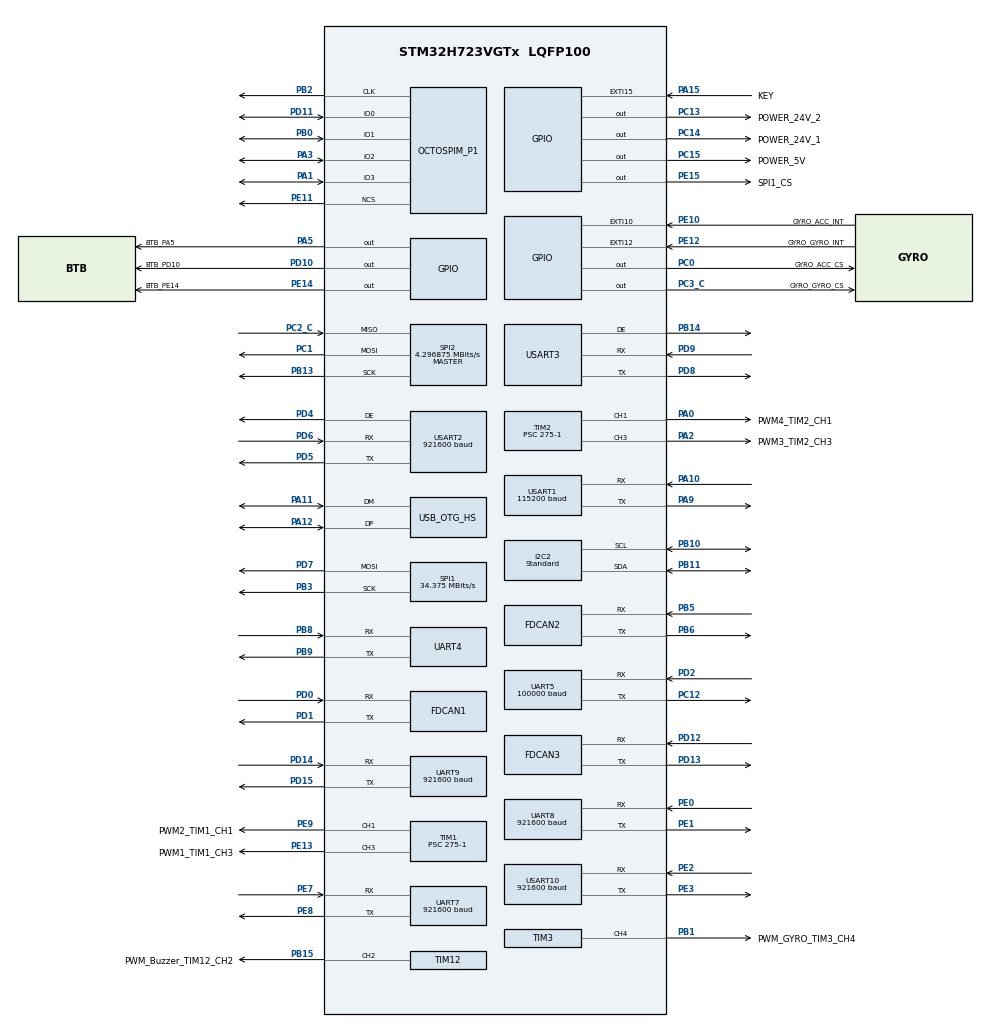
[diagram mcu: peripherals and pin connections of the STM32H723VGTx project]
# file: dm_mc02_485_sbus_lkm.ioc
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CORTEX_M7.BaseAddress-Cortex_Memory_Protection_Unit_Region0_Settings=0x24000000
CORTEX_M7.CPU_DCache=Disabled
CORTEX_M7.CPU_ICache=Disabled
CORTEX_M7.Enable-Cortex_Memory_Protection_Unit_Region0_Settings=MPU_REGION_ENABLE
CORTEX_M7.IsBufferable-Cortex_Memory_Protection_Unit_Region0_Settings=MPU_ACCESS_BUFFERABLE
CORTEX_M7.IsCacheable-Cortex_Memory_Protection_Unit_Region0_Settings=MPU_ACCESS_CACHEABLE
CORTEX_M7.MPU_Control=__NULL
CORTEX_M7.Size-Cortex_Memory_Protection_Unit_Region0_Settings=MPU_REGION_SIZE_512B
CORTEX_M7.TypeExtField-Cortex_Memory_Protection_Unit_Region0_Settings=MPU_TEX_LEVEL1
Dma.Request0=USART1_RX
Dma.Request1=USART1_TX
Dma.Request10=USART10_RX
Dma.Request11=USART10_TX
Dma.Request12=USART2_RX
Dma.Request13=USART2_TX
Dma.Request2=UART4_RX
Dma.Request3=UART4_TX
Dma.Request4=UART7_RX
Dma.Request5=UART7_TX
Dma.Request6=UART8_RX
Dma.Request7=UART8_TX
Dma.Request8=UART9_RX
Dma.Request9=UART9_TX
Dma.UART4_RX.2.Direction=DMA_PERIPH_TO_MEMORY
Dma.UART4_RX.2.EventEnable=DISABLE
Dma.UART4_RX.2.FIFOMode=DMA_FIFOMODE_DISABLE
Dma.UART4_RX.2.Instance=DMA1_Stream3
Dma.UART4_RX.2.MemDataAlignment=DMA_MDATAALIGN_BYTE
Dma.UART4_RX.2.MemInc=DMA_MINC_ENABLE
Dma.UART4_RX.2.Mode=DMA_NORMAL
Dma.UART4_RX.2.PeriphDataAlignment=DMA_PDATAALIGN_BYTE
Dma.UART4_RX.2.PeriphInc=DMA_PINC_DISABLE
Dma.UART4_RX.2.Polarity=HAL_DMAMUX_REQ_GEN_RISING
Dma.UART4_RX.2.Priority=DMA_PRIORITY_LOW
Dma.UART4_RX.2.RequestNumber=1
Dma.UART4_RX.2.SignalID=NONE
Dma.UART4_RX.2.SyncEnable=DISABLE
Dma.UART4_RX.2.SyncPolarity=HAL_DMAMUX_SYNC_NO_EVENT
Dma.UART4_RX.2.SyncRequestNumber=1
Dma.UART4_RX.2.SyncSignalID=NONE
Dma.UART4_TX.3.Direction=DMA_MEMORY_TO_PERIPH
Dma.UART4_TX.3.EventEnable=DISABLE
Dma.UART4_TX.3.FIFOMode=DMA_FIFOMODE_ENABLE
Dma.UART4_TX.3.FIFOThreshold=DMA_FIFO_THRESHOLD_HALFFULL
Dma.UART4_TX.3.Instance=DMA1_Stream4
Dma.UART4_TX.3.MemBurst=DMA_MBURST_SINGLE
Dma.UART4_TX.3.MemDataAlignment=DMA_MDATAALIGN_BYTE
Dma.UART4_TX.3.MemInc=DMA_MINC_ENABLE
Dma.UART4_TX.3.Mode=DMA_NORMAL
Dma.UART4_TX.3.PeriphBurst=DMA_PBURST_SINGLE
Dma.UART4_TX.3.PeriphDataAlignment=DMA_PDATAALIGN_BYTE
Dma.UART4_TX.3.PeriphInc=DMA_PINC_DISABLE
Dma.UART4_TX.3.Polarity=HAL_DMAMUX_REQ_GEN_RISING
Dma.UART4_TX.3.Priority=DMA_PRIORITY_LOW
Dma.UART4_TX.3.RequestNumber=1
Dma.UART4_TX.3.SignalID=NONE
Dma.UART4_TX.3.SyncEnable=DISABLE
Dma.UART4_TX.3.SyncPolarity=HAL_DMAMUX_SYNC_NO_EVENT
Dma.UART4_TX.3.SyncRequestNumber=1
Dma.UART4_TX.3.SyncSignalID=NONE
Dma.UART7_RX.4.Direction=DMA_PERIPH_TO_MEMORY
Dma.UART7_RX.4.EventEnable=DISABLE
Dma.UART7_RX.4.FIFOMode=DMA_FIFOMODE_DISABLE
Dma.UART7_RX.4.Instance=DMA1_Stream5
Dma.UART7_RX.4.MemDataAlignment=DMA_MDATAALIGN_BYTE
Dma.UART7_RX.4.MemInc=DMA_MINC_ENABLE
Dma.UART7_RX.4.Mode=DMA_NORMAL
Dma.UART7_RX.4.PeriphDataAlignment=DMA_PDATAALIGN_BYTE
Dma.UART7_RX.4.PeriphInc=DMA_PINC_DISABLE
Dma.UART7_RX.4.Polarity=HAL_DMAMUX_REQ_GEN_RISING
Dma.UART7_RX.4.Priority=DMA_PRIORITY_LOW
Dma.UART7_RX.4.RequestNumber=1
Dma.UART7_RX.4.SignalID=NONE
Dma.UART7_RX.4.SyncEnable=DISABLE
Dma.UART7_RX.4.SyncPolarity=HAL_DMAMUX_SYNC_NO_EVENT
Dma.UART7_RX.4.SyncRequestNumber=1
Dma.UART7_RX.4.SyncSignalID=NONE
Dma.UART7_TX.5.Direction=DMA_MEMORY_TO_PERIPH
Dma.UART7_TX.5.EventEnable=DISABLE
Dma.UART7_TX.5.FIFOMode=DMA_FIFOMODE_ENABLE
Dma.UART7_TX.5.FIFOThreshold=DMA_FIFO_THRESHOLD_HALFFULL
Dma.UART7_TX.5.Instance=DMA1_Stream6
Dma.UART7_TX.5.MemBurst=DMA_MBURST_SINGLE
Dma.UART7_TX.5.MemDataAlignment=DMA_MDATAALIGN_BYTE
Dma.UART7_TX.5.MemInc=DMA_MINC_ENABLE
Dma.UART7_TX.5.Mode=DMA_NORMAL
Dma.UART7_TX.5.PeriphBurst=DMA_PBURST_SINGLE
Dma.UART7_TX.5.PeriphDataAlignment=DMA_PDATAALIGN_BYTE
Dma.UART7_TX.5.PeriphInc=DMA_PINC_DISABLE
Dma.UART7_TX.5.Polarity=HAL_DMAMUX_REQ_GEN_RISING
Dma.UART7_TX.5.Priority=DMA_PRIORITY_LOW
Dma.UART7_TX.5.RequestNumber=1
Dma.UART7_TX.5.SignalID=NONE
Dma.UART7_TX.5.SyncEnable=DISABLE
Dma.UART7_TX.5.SyncPolarity=HAL_DMAMUX_SYNC_NO_EVENT
Dma.UART7_TX.5.SyncRequestNumber=1
Dma.UART7_TX.5.SyncSignalID=NONE
Dma.UART8_RX.6.Direction=DMA_PERIPH_TO_MEMORY
Dma.UART8_RX.6.EventEnable=DISABLE
Dma.UART8_RX.6.FIFOMode=DMA_FIFOMODE_DISABLE
Dma.UART8_RX.6.Instance=DMA1_Stream7
Dma.UART8_RX.6.MemDataAlignment=DMA_MDATAALIGN_BYTE
Dma.UART8_RX.6.MemInc=DMA_MINC_ENABLE
Dma.UART8_RX.6.Mode=DMA_NORMAL
Dma.UART8_RX.6.PeriphDataAlignment=DMA_PDATAALIGN_BYTE
Dma.UART8_RX.6.PeriphInc=DMA_PINC_DISABLE
Dma.UART8_RX.6.Polarity=HAL_DMAMUX_REQ_GEN_RISING
Dma.UART8_RX.6.Priority=DMA_PRIORITY_LOW
Dma.UART8_RX.6.RequestNumber=1
Dma.UART8_RX.6.SignalID=NONE
Dma.UART8_RX.6.SyncEnable=DISABLE
Dma.UART8_RX.6.SyncPolarity=HAL_DMAMUX_SYNC_NO_EVENT
Dma.UART8_RX.6.SyncRequestNumber=1
Dma.UART8_RX.6.SyncSignalID=NONE
Dma.UART8_TX.7.Direction=DMA_MEMORY_TO_PERIPH
Dma.UART8_TX.7.EventEnable=DISABLE
Dma.UART8_TX.7.FIFOMode=DMA_FIFOMODE_ENABLE
Dma.UART8_TX.7.FIFOThreshold=DMA_FIFO_THRESHOLD_HALFFULL
Dma.UART8_TX.7.Instance=DMA2_Stream0
Dma.UART8_TX.7.MemBurst=DMA_MBURST_SINGLE
Dma.UART8_TX.7.MemDataAlignment=DMA_MDATAALIGN_BYTE
Dma.UART8_TX.7.MemInc=DMA_MINC_ENABLE
Dma.UART8_TX.7.Mode=DMA_NORMAL
Dma.UART8_TX.7.PeriphBurst=DMA_PBURST_SINGLE
Dma.UART8_TX.7.PeriphDataAlignment=DMA_PDATAALIGN_BYTE
Dma.UART8_TX.7.PeriphInc=DMA_PINC_DISABLE
Dma.UART8_TX.7.Polarity=HAL_DMAMUX_REQ_GEN_RISING
Dma.UART8_TX.7.Priority=DMA_PRIORITY_LOW
Dma.UART8_TX.7.RequestNumber=1
Dma.UART8_TX.7.SignalID=NONE
Dma.UART8_TX.7.SyncEnable=DISABLE
Dma.UART8_TX.7.SyncPolarity=HAL_DMAMUX_SYNC_NO_EVENT
Dma.UART8_TX.7.SyncRequestNumber=1
Dma.UART8_TX.7.SyncSignalID=NONE
Dma.UART9_RX.8.Direction=DMA_PERIPH_TO_MEMORY
Dma.UART9_RX.8.EventEnable=DISABLE
Dma.UART9_RX.8.FIFOMode=DMA_FIFOMODE_DISABLE
Dma.UART9_RX.8.Instance=DMA2_Stream1
Dma.UART9_RX.8.MemDataAlignment=DMA_MDATAALIGN_BYTE
Dma.UART9_RX.8.MemInc=DMA_MINC_ENABLE
Dma.UART9_RX.8.Mode=DMA_NORMAL
Dma.UART9_RX.8.PeriphDataAlignment=DMA_PDATAALIGN_BYTE
Dma.UART9_RX.8.PeriphInc=DMA_PINC_DISABLE
Dma.UART9_RX.8.Polarity=HAL_DMAMUX_REQ_GEN_RISING
Dma.UART9_RX.8.Priority=DMA_PRIORITY_LOW
Dma.UART9_RX.8.RequestNumber=1
Dma.UART9_RX.8.SignalID=NONE
Dma.UART9_RX.8.SyncEnable=DISABLE
Dma.UART9_RX.8.SyncPolarity=HAL_DMAMUX_SYNC_NO_EVENT
Dma.UART9_RX.8.SyncRequestNumber=1
Dma.UART9_RX.8.SyncSignalID=NONE
Dma.UART9_TX.9.Direction=DMA_MEMORY_TO_PERIPH
Dma.UART9_TX.9.EventEnable=DISABLE
Dma.UART9_TX.9.FIFOMode=DMA_FIFOMODE_ENABLE
Dma.UART9_TX.9.FIFOThreshold=DMA_FIFO_THRESHOLD_HALFFULL
Dma.UART9_TX.9.Instance=DMA2_Stream2
Dma.UART9_TX.9.MemBurst=DMA_MBURST_SINGLE
Dma.UART9_TX.9.MemDataAlignment=DMA_MDATAALIGN_BYTE
Dma.UART9_TX.9.MemInc=DMA_MINC_ENABLE
Dma.UART9_TX.9.Mode=DMA_NORMAL
Dma.UART9_TX.9.PeriphBurst=DMA_PBURST_SINGLE
Dma.UART9_TX.9.PeriphDataAlignment=DMA_PDATAALIGN_BYTE
Dma.UART9_TX.9.PeriphInc=DMA_PINC_DISABLE
Dma.UART9_TX.9.Polarity=HAL_DMAMUX_REQ_GEN_RISING
Dma.UART9_TX.9.Priority=DMA_PRIORITY_LOW
Dma.UART9_TX.9.RequestNumber=1
Dma.UART9_TX.9.SignalID=NONE
Dma.UART9_TX.9.SyncEnable=DISABLE
Dma.UART9_TX.9.SyncPolarity=HAL_DMAMUX_SYNC_NO_EVENT
Dma.UART9_TX.9.SyncRequestNumber=1
Dma.UART9_TX.9.SyncSignalID=NONE
Dma.USART10_RX.10.Direction=DMA_PERIPH_TO_MEMORY
Dma.USART10_RX.10.EventEnable=DISABLE
Dma.USART10_RX.10.FIFOMode=DMA_FIFOMODE_DISABLE
Dma.USART10_RX.10.Instance=DMA2_Stream3
Dma.USART10_RX.10.MemDataAlignment=DMA_MDATAALIGN_BYTE
Dma.USART10_RX.10.MemInc=DMA_MINC_ENABLE
Dma.USART10_RX.10.Mode=DMA_NORMAL
Dma.USART10_RX.10.PeriphDataAlignment=DMA_PDATAALIGN_BYTE
Dma.USART10_RX.10.PeriphInc=DMA_PINC_DISABLE
Dma.USART10_RX.10.Polarity=HAL_DMAMUX_REQ_GEN_RISING
Dma.USART10_RX.10.Priority=DMA_PRIORITY_LOW
Dma.USART10_RX.10.RequestNumber=1
Dma.USART10_RX.10.SignalID=NONE
Dma.USART10_RX.10.SyncEnable=DISABLE
Dma.USART10_RX.10.SyncPolarity=HAL_DMAMUX_SYNC_NO_EVENT
Dma.USART10_RX.10.SyncRequestNumber=1
Dma.USART10_RX.10.SyncSignalID=NONE
Dma.USART10_TX.11.Direction=DMA_MEMORY_TO_PERIPH
Dma.USART10_TX.11.EventEnable=DISABLE
Dma.USART10_TX.11.FIFOMode=DMA_FIFOMODE_ENABLE
Dma.USART10_TX.11.FIFOThreshold=DMA_FIFO_THRESHOLD_HALFFULL
Dma.USART10_TX.11.Instance=DMA2_Stream4
Dma.USART10_TX.11.MemBurst=DMA_MBURST_SINGLE
Dma.USART10_TX.11.MemDataAlignment=DMA_MDATAALIGN_BYTE
Dma.USART10_TX.11.MemInc=DMA_MINC_ENABLE
Dma.USART10_TX.11.Mode=DMA_NORMAL
Dma.USART10_TX.11.PeriphBurst=DMA_PBURST_SINGLE
Dma.USART10_TX.11.PeriphDataAlignment=DMA_PDATAALIGN_BYTE
Dma.USART10_TX.11.PeriphInc=DMA_PINC_DISABLE
Dma.USART10_TX.11.Polarity=HAL_DMAMUX_REQ_GEN_RISING
Dma.USART10_TX.11.Priority=DMA_PRIORITY_LOW
Dma.USART10_TX.11.RequestNumber=1
Dma.USART10_TX.11.SignalID=NONE
Dma.USART10_TX.11.SyncEnable=DISABLE
Dma.USART10_TX.11.SyncPolarity=HAL_DMAMUX_SYNC_NO_EVENT
Dma.USART10_TX.11.SyncRequestNumber=1
Dma.USART10_TX.11.SyncSignalID=NONE
Dma.USART1_RX.0.Direction=DMA_PERIPH_TO_MEMORY
Dma.USART1_RX.0.EventEnable=DISABLE
Dma.USART1_RX.0.FIFOMode=DMA_FIFOMODE_DISABLE
Dma.USART1_RX.0.Instance=DMA1_Stream1
Dma.USART1_RX.0.MemDataAlignment=DMA_MDATAALIGN_BYTE
Dma.USART1_RX.0.MemInc=DMA_MINC_ENABLE
Dma.USART1_RX.0.Mode=DMA_NORMAL
Dma.USART1_RX.0.PeriphDataAlignment=DMA_PDATAALIGN_BYTE
Dma.USART1_RX.0.PeriphInc=DMA_PINC_DISABLE
Dma.USART1_RX.0.Polarity=HAL_DMAMUX_REQ_GEN_RISING
Dma.USART1_RX.0.Priority=DMA_PRIORITY_LOW
Dma.USART1_RX.0.RequestNumber=1
Dma.USART1_RX.0.SignalID=NONE
Dma.USART1_RX.0.SyncEnable=DISABLE
Dma.USART1_RX.0.SyncPolarity=HAL_DMAMUX_SYNC_NO_EVENT
Dma.USART1_RX.0.SyncRequestNumber=1
Dma.USART1_RX.0.SyncSignalID=NONE
Dma.USART1_TX.1.Direction=DMA_MEMORY_TO_PERIPH
Dma.USART1_TX.1.EventEnable=DISABLE
Dma.USART1_TX.1.FIFOMode=DMA_FIFOMODE_ENABLE
Dma.USART1_TX.1.FIFOThreshold=DMA_FIFO_THRESHOLD_HALFFULL
Dma.USART1_TX.1.Instance=DMA1_Stream2
Dma.USART1_TX.1.MemBurst=DMA_MBURST_SINGLE
Dma.USART1_TX.1.MemDataAlignment=DMA_MDATAALIGN_BYTE
Dma.USART1_TX.1.MemInc=DMA_MINC_ENABLE
Dma.USART1_TX.1.Mode=DMA_NORMAL
Dma.USART1_TX.1.PeriphBurst=DMA_PBURST_SINGLE
Dma.USART1_TX.1.PeriphDataAlignment=DMA_PDATAALIGN_BYTE
Dma.USART1_TX.1.PeriphInc=DMA_PINC_DISABLE
Dma.USART1_TX.1.Polarity=HAL_DMAMUX_REQ_GEN_RISING
Dma.USART1_TX.1.Priority=DMA_PRIORITY_LOW
Dma.USART1_TX.1.RequestNumber=1
Dma.USART1_TX.1.SignalID=NONE
Dma.USART1_TX.1.SyncEnable=DISABLE
Dma.USART1_TX.1.SyncPolarity=HAL_DMAMUX_SYNC_NO_EVENT
Dma.USART1_TX.1.SyncRequestNumber=1
Dma.USART1_TX.1.SyncSignalID=NONE
Dma.USART2_RX.12.Direction=DMA_PERIPH_TO_MEMORY
Dma.USART2_RX.12.EventEnable=DISABLE
Dma.USART2_RX.12.FIFOMode=DMA_FIFOMODE_DISABLE
Dma.USART2_RX.12.Instance=DMA1_Stream0
Dma.USART2_RX.12.MemDataAlignment=DMA_MDATAALIGN_BYTE
Dma.USART2_RX.12.MemInc=DMA_MINC_ENABLE
Dma.USART2_RX.12.Mode=DMA_NORMAL
Dma.USART2_RX.12.PeriphDataAlignment=DMA_PDATAALIGN_BYTE
Dma.USART2_RX.12.PeriphInc=DMA_PINC_DISABLE
Dma.USART2_RX.12.Polarity=HAL_DMAMUX_REQ_GEN_RISING
Dma.USART2_RX.12.Priority=DMA_PRIORITY_LOW
Dma.USART2_RX.12.RequestNumber=1
Dma.USART2_RX.12.SignalID=NONE
Dma.USART2_RX.12.SyncEnable=DISABLE
Dma.USART2_RX.12.SyncPolarity=HAL_DMAMUX_SYNC_NO_EVENT
Dma.USART2_RX.12.SyncRequestNumber=1
Dma.USART2_RX.12.SyncSignalID=NONE
Dma.USART2_TX.13.Direction=DMA_MEMORY_TO_PERIPH
Dma.USART2_TX.13.EventEnable=DISABLE
Dma.USART2_TX.13.FIFOMode=DMA_FIFOMODE_DISABLE
Dma.USART2_TX.13.Instance=DMA2_Stream5
Dma.USART2_TX.13.MemDataAlignment=DMA_MDATAALIGN_BYTE
Dma.USART2_TX.13.MemInc=DMA_MINC_ENABLE
Dma.USART2_TX.13.Mode=DMA_NORMAL
Dma.USART2_TX.13.PeriphDataAlignment=DMA_PDATAALIGN_BYTE
Dma.USART2_TX.13.PeriphInc=DMA_PINC_DISABLE
Dma.USART2_TX.13.Polarity=HAL_DMAMUX_REQ_GEN_RISING
Dma.USART2_TX.13.Priority=DMA_PRIORITY_LOW
Dma.USART2_TX.13.RequestNumber=1
Dma.USART2_TX.13.SignalID=NONE
Dma.USART2_TX.13.SyncEnable=DISABLE
Dma.USART2_TX.13.SyncPolarity=HAL_DMAMUX_SYNC_NO_EVENT
Dma.USART2_TX.13.SyncRequestNumber=1
Dma.USART2_TX.13.SyncSignalID=NONE
FDCAN1.AutoRetransmission=ENABLE
FDCAN1.CalculateBaudRateNominal=1000000
FDCAN1.CalculateTimeBitNominal=1000
FDCAN1.CalculateTimeQuantumNominal=62.5
FDCAN1.NominalPrescaler=6
FDCAN1.NominalTimeSeg1=11
FDCAN1.NominalTimeSeg2=4
FDCAN1.RxFifo0ElmtsNbr=16
FDCAN1.StdFiltersNbr=1
FDCAN1.TxFifoQueueElmtsNbr=16
FDCAN2.AutoRetransmission=ENABLE
FDCAN2.CalculateBaudRateNominal=1000000
FDCAN2.CalculateTimeBitNominal=1000
FDCAN2.CalculateTimeQuantumNominal=62.5
FDCAN2.MessageRAMOffset=129
FDCAN2.NominalPrescaler=6
FDCAN2.NominalTimeSeg1=11
FDCAN2.NominalTimeSeg2=4
FDCAN2.RxFifo0ElmtsNbr=16
FDCAN2.StdFiltersNbr=1
FDCAN2.TxFifoQueueElmtsNbr=16
FDCAN3.AutoRetransmission=ENABLE
FDCAN3.CalculateBaudRateNominal=1000000
FDCAN3.CalculateTimeBitNominal=1000
FDCAN3.CalculateTimeQuantumNominal=62.5
FDCAN3.MessageRAMOffset=258
FDCAN3.NominalPrescaler=6
FDCAN3.NominalTimeSeg1=11
FDCAN3.NominalTimeSeg2=4
FDCAN3.RxFifo0ElmtsNbr=16
FDCAN3.StdFiltersNbr=1
FDCAN3.TxFifoQueueElmtsNbr=16
FREERTOS.INCLUDE_eTaskGetState=1
FREERTOS.INCLUDE_uxTaskGetStackHighWaterMark=1
FREERTOS.INCLUDE_vTaskDelayUntil=1
FREERTOS.INCLUDE_xQueueGetMutexHolder=1
FREERTOS.INCLUDE_xTaskGetCurrentTaskHandle=1
FREERTOS.INCLUDE_xTimerPendFunctionCall=1
FREERTOS.Tasks01=defaultTask,24,512,StartDefaultTask,As weak,NULL,Dynamic,NULL,NULL
FREERTOS.configCHECK_FOR_STACK_OVERFLOW=2
FREERTOS.configENABLE_FPU=1
FREERTOS.configTOTAL_HEAP_SIZE=49152
FREERTOS.configUSE_COUNTING_SEMAPHORES=1
FREERTOS.configUSE_MALLOC_FAILED_HOOK=1
FREERTOS.configUSE_NEWLIB_REENTRANT=1
FREERTOS.configUSE_RECURSIVE_MUTEXES=1
FREERTOS.configUSE_TIMERS=1
FREERTOS.configUSE_TRACE_FACILITY=1
I2C2.I2C_Speed_Mode=I2C_Standard
I2C2.Timing=0x60404E72
Mcu.Family=STM32H7
Mcu.Name=STM32H723VGTx
Mcu.Package=LQFP100
NVIC.DMA1_Stream0_IRQn=true\:5\:0\:false\:false\:true\:true\:false\:true\:true
NVIC.DMA1_Stream1_IRQn=true\:5\:0\:false\:false\:true\:true\:false\:true\:true
NVIC.DMA1_Stream2_IRQn=true\:5\:0\:false\:false\:true\:true\:false\:true\:true
NVIC.DMA1_Stream3_IRQn=true\:5\:0\:false\:false\:true\:true\:false\:true\:true
NVIC.DMA1_Stream4_IRQn=true\:5\:0\:false\:false\:true\:true\:false\:true\:true
NVIC.DMA1_Stream5_IRQn=true\:5\:0\:false\:false\:true\:true\:false\:true\:true
NVIC.DMA1_Stream6_IRQn=true\:5\:0\:false\:false\:true\:true\:false\:true\:true
NVIC.DMA1_Stream7_IRQn=true\:5\:0\:false\:false\:true\:true\:false\:true\:true
NVIC.DMA2_Stream0_IRQn=true\:5\:0\:false\:false\:true\:true\:false\:true\:true
NVIC.DMA2_Stream1_IRQn=true\:5\:0\:false\:false\:true\:true\:false\:true\:true
NVIC.DMA2_Stream2_IRQn=true\:5\:0\:false\:false\:true\:true\:false\:true\:true
NVIC.DMA2_Stream3_IRQn=true\:5\:0\:false\:false\:true\:true\:false\:true\:true
NVIC.DMA2_Stream4_IRQn=true\:5\:0\:false\:false\:true\:true\:false\:true\:true
NVIC.DMA2_Stream5_IRQn=true\:5\:0\:false\:false\:true\:true\:false\:true\:true
NVIC.EXTI15_10_IRQn=true\:5\:0\:false\:false\:true\:true\:true\:true\:true
NVIC.FDCAN1_IT0_IRQn=true\:5\:0\:false\:false\:true\:true\:true\:true\:true
NVIC.FDCAN1_IT1_IRQn=true\:5\:0\:false\:false\:true\:true\:true\:true\:true
NVIC.FDCAN2_IT0_IRQn=true\:5\:0\:false\:false\:true\:true\:true\:true\:true
NVIC.FDCAN2_IT1_IRQn=true\:5\:0\:false\:false\:true\:true\:true\:true\:true
NVIC.FDCAN3_IT0_IRQn=true\:5\:0\:false\:false\:true\:true\:true\:true\:true
NVIC.FDCAN3_IT1_IRQn=true\:5\:0\:false\:false\:true\:true\:true\:true\:true
NVIC.PriorityGroup=NVIC_PRIORITYGROUP_4
NVIC.TIM8_UP_TIM13_IRQn=true\:15\:0\:false\:false\:true\:false\:false\:true\:true
NVIC.TimeBase=TIM8_UP_TIM13_IRQn
NVIC.TimeBaseIP=TIM8
NVIC.UART4_IRQn=true\:5\:0\:false\:false\:true\:true\:true\:true\:true
NVIC.UART5_IRQn=true\:5\:0\:false\:false\:true\:true\:true\:true\:true
NVIC.UART7_IRQn=true\:5\:0\:true\:false\:true\:true\:true\:true\:true
NVIC.UART8_IRQn=true\:5\:0\:false\:false\:true\:true\:true\:true\:true
NVIC.UART9_IRQn=true\:5\:0\:false\:false\:true\:true\:true\:true\:true
NVIC.USART10_IRQn=true\:5\:0\:true\:false\:true\:true\:true\:true\:true
NVIC.USART1_IRQn=true\:5\:0\:true\:false\:true\:true\:true\:true\:true
NVIC.USART2_IRQn=true\:5\:0\:false\:false\:true\:true\:true\:true\:true
OCTOSPI2.ClockMode=HAL_OSPI_CLOCK_MODE_3
OCTOSPI2.ClockPrescaler=3
OCTOSPI2.DeviceSize=23
OCTOSPI2.DeviceType=SPI_DEVICE_FLASH
OCTOSPI2.FifoThreshold=8
OCTOSPI2.SampleShifting=HAL_OSPI_SAMPLE_SHIFTING_HALFCYCLE
PA0.GPIO_Label=PWM4_TIM2_CH1
PA0.Signal=S_TIM2_CH1_ETR
PA1.Mode=OCTOSPI2_IOL_Port1L
PA1.Signal=OCTOSPIM_P1_IO3
PA10.Mode=Asynchronous
PA10.Signal=USART1_RX
PA11.Mode=Device_Only_FS
PA11.Signal=USB_OTG_HS_DM
PA12.Mode=Device_Only_FS
PA12.Signal=USB_OTG_HS_DP
PA13(JTMS/SWDIO).Mode=Serial_Wire
PA13(JTMS/SWDIO).Signal=DEBUG_JTMS-SWDIO
PA14(JTCK/SWCLK).Mode=Serial_Wire
PA14(JTCK/SWCLK).Signal=DEBUG_JTCK-SWCLK
PA15(JTDI).GPIO_Label=KEY
PA15(JTDI).GPIO_ModeDefaultEXTI=GPIO_MODE_IT_RISING
PA15(JTDI).Signal=GPXTI15
PA2.GPIO_Label=PWM3_TIM2_CH3
PA2.Signal=S_TIM2_CH3
PA3.Mode=OCTOSPI2_IOL_Port1L
PA3.Signal=OCTOSPIM_P1_IO2
PA5.GPIO_Label=BTB_PA5
PA5.Signal=GPIO_Output
PA7.Signal=S_TIM14_CH1
PA9.Mode=Asynchronous
PA9.Signal=USART1_TX
PB0.Mode=OCTOSPI2_IOL_Port1L
PB0.Signal=OCTOSPIM_P1_IO1
PB1.GPIO_Label=PWM_GYRO_TIM3_CH4
PB1.Signal=S_TIM3_CH4
PB10.Mode=I2C
PB10.Signal=I2C2_SCL
PB11.Mode=I2C
PB11.Signal=I2C2_SDA
PB13.GPIO_Speed=GPIO_SPEED_FREQ_VERY_HIGH
PB13.Mode=Full_Duplex_Master
PB13.Signal=SPI2_SCK
PB14.Mode=Hardware Flow Control (RS485)
PB14.Signal=USART3_DE
PB15.GPIO_Label=PWM_Buzzer_TIM12_CH2
PB15.Signal=S_TIM12_CH2
PB2.Mode=O2_P1_CLK
PB2.Signal=OCTOSPIM_P1_CLK
PB3(JTDO/TRACESWO).GPIO_Speed=GPIO_SPEED_FREQ_VERY_HIGH
PB3(JTDO/TRACESWO).Mode=TX_Only_Simplex_Unidirect_Master
PB3(JTDO/TRACESWO).Signal=SPI1_SCK
PB5.Mode=FDCAN_Activate
PB5.Signal=FDCAN2_RX
PB6.Mode=FDCAN_Activate
PB6.Signal=FDCAN2_TX
PB8.Mode=Asynchronous
PB8.Signal=UART4_RX
PB9.Mode=Asynchronous
PB9.Signal=UART4_TX
PC0.GPIO_Label=GYRO_ACC_CS
PC0.GPIO_Speed=GPIO_SPEED_FREQ_VERY_HIGH
PC0.PinState=GPIO_PIN_SET
PC0.Signal=GPIO_Output
PC1.GPIO_Speed=GPIO_SPEED_FREQ_VERY_HIGH
PC1.Mode=Full_Duplex_Master
PC1.Signal=SPI2_MOSI
PC12.Mode=Asynchronous
PC12.Signal=UART5_TX
PC13.GPIO_Label=POWER_24V_2
PC13.PinState=GPIO_PIN_SET
PC13.Signal=GPIO_Output
PC14-OSC32_IN.GPIO_Label=POWER_24V_1
PC14-OSC32_IN.PinState=GPIO_PIN_SET
PC14-OSC32_IN.Signal=GPIO_Output
PC15-OSC32_OUT.GPIO_Label=POWER_5V
PC15-OSC32_OUT.PinState=GPIO_PIN_SET
PC15-OSC32_OUT.Signal=GPIO_Output
PC2_C.GPIO_Speed=GPIO_SPEED_FREQ_VERY_HIGH
PC2_C.Mode=Full_Duplex_Master
PC2_C.Signal=SPI2_MISO
PC3_C.GPIO_Label=GYRO_GYRO_CS
PC3_C.GPIO_Speed=GPIO_SPEED_FREQ_VERY_HIGH
PC3_C.PinState=GPIO_PIN_SET
PC3_C.Signal=GPIO_Output
PD0.Mode=FDCAN_Activate
PD0.Signal=FDCAN1_RX
PD1.Mode=FDCAN_Activate
PD1.Signal=FDCAN1_TX
PD10.GPIO_Label=BTB_PD10
PD10.Signal=GPIO_Output
PD11.Mode=OCTOSPI2_IOL_Port1L
PD11.Signal=OCTOSPIM_P1_IO0
PD12.Mode=FDCAN_Activate
PD12.Signal=FDCAN3_RX
PD13.Mode=FDCAN_Activate
PD13.Signal=FDCAN3_TX
PD14.GPIO_Speed=GPIO_SPEED_FREQ_VERY_HIGH
PD14.Mode=Asynchronous
PD14.Signal=UART9_RX
PD15.GPIO_Speed=GPIO_SPEED_FREQ_VERY_HIGH
PD15.Mode=Asynchronous
PD15.Signal=UART9_TX
PD2.Mode=Asynchronous
PD2.Signal=UART5_RX
PD4.Mode=Hardware Flow Control (RS485)
PD4.Signal=USART2_DE
PD5.Mode=Asynchronous
PD5.Signal=USART2_TX
PD6.Mode=Asynchronous
PD6.Signal=USART2_RX
PD7.GPIO_Speed=GPIO_SPEED_FREQ_VERY_HIGH
PD7.Mode=TX_Only_Simplex_Unidirect_Master
PD7.Signal=SPI1_MOSI
PD8.Mode=Asynchronous
PD8.Signal=USART3_TX
PD9.Mode=Asynchronous
PD9.Signal=USART3_RX
PE0.GPIO_Speed=GPIO_SPEED_FREQ_VERY_HIGH
PE0.Mode=Asynchronous
PE0.Signal=UART8_RX
PE1.GPIO_Speed=GPIO_SPEED_FREQ_VERY_HIGH
PE1.Mode=Asynchronous
PE1.Signal=UART8_TX
PE10.GPIO_Label=GYRO_ACC_INT
PE10.Signal=GPXTI10
PE11.Mode=OCTOSPI2_Port1_NCS
PE11.Signal=OCTOSPIM_P1_NCS
PE12.GPIO_Label=GYRO_GYRO_INT
PE12.Signal=GPXTI12
PE13.GPIO_Label=PWM1_TIM1_CH3
PE13.Signal=S_TIM1_CH3
PE14.GPIO_Label=BTB_PE14
PE14.Signal=GPIO_Output
PE15.GPIO_Label=SPI1_CS
PE15.Signal=GPIO_Output
PE2.Mode=Asynchronous
PE2.Signal=USART10_RX
PE3.Mode=Asynchronous
PE3.Signal=USART10_TX
PE7.Mode=Asynchronous
PE7.Signal=UART7_RX
PE8.Mode=Asynchronous
PE8.Signal=UART7_TX
PE9.GPIO_Label=PWM2_TIM1_CH1
PE9.Signal=S_TIM1_CH1
PH0-OSC_IN.Mode=HSE-External-Oscillator
PH0-OSC_IN.Signal=RCC_OSC_IN
PH1-OSC_OUT.Mode=HSE-External-Oscillator
PH1-OSC_OUT.Signal=RCC_OSC_OUT
ProjectManager.HeapSize=0x800
ProjectManager.StackSize=0x800
ProjectManager.TargetToolchain=CMake
RCC.ADCFreq_Value=96000000
RCC.APB1Freq_Value=137500000
RCC.APB2Freq_Value=137500000
RCC.APB3Freq_Value=137500000
RCC.APB4Freq_Value=137500000
RCC.CortexFreq_Value=550000000
RCC.D1PPRE=RCC_APB3_DIV2
RCC.D2PPRE1=RCC_APB1_DIV2
RCC.D2PPRE2=RCC_APB2_DIV2
RCC.D3PPRE=RCC_APB4_DIV2
RCC.DIVM1=3
RCC.DIVM2=2
RCC.DIVN1=68
RCC.DIVN2=16
RCC.DIVP1=1
RCC.DIVQ1=4
RCC.FDCANCLockSelection=RCC_FDCANCLKSOURCE_PLL2
RCC.HCLKFreq_Value=275000000
RCC.HPRE=RCC_HCLK_DIV2
RCC.HSE_VALUE=24000000
RCC.PLL2FRACN=0
RCC.PLL2_VCI_Range-AdvancedSettings=RCC_PLL2VCIRANGE_0
RCC.PLL2_VCO_SEL-AdvancedSettings=RCC_PLL2VCOMEDIUM
RCC.PLL3FRACN=0
RCC.PLL3_VCI_Range-AdvancedSettings=RCC_PLL3VCIRANGE_3
RCC.PLL3_VCO_SEL-AdvancedSettings=RCC_PLL3VCOMEDIUM
RCC.PLLFRACN=6144
RCC.PLLSourceVirtual=RCC_PLLSOURCE_HSE
RCC.SPI6CLockSelection=RCC_SPI6CLKSOURCE_HSE
RCC.SYSCLKFreq_VALUE=550000000
RCC.SYSCLKSource=RCC_SYSCLKSOURCE_PLLCLK
RCC.USBCLockSelection=RCC_USBCLKSOURCE_HSI48
RCC.USBFreq_Value=48000000
SH.S_TIM12_CH2.0=TIM12_CH2,PWM Generation2 CH2
SH.S_TIM14_CH1.0=TIM14_CH1
SH.S_TIM1_CH1.0=TIM1_CH1,PWM Generation1 CH1
SH.S_TIM1_CH3.0=TIM1_CH3,PWM Generation3 CH3
SH.S_TIM2_CH1_ETR.0=TIM2_CH1,PWM Generation1 CH1
SH.S_TIM2_CH3.0=TIM2_CH3,PWM Generation3 CH3
SH.S_TIM3_CH4.0=TIM3_CH4,PWM Generation4 CH4
SPI1.BaudRatePrescaler=SPI_BAUDRATEPRESCALER_4
SPI1.CLKPolarity=SPI_POLARITY_HIGH
SPI1.CalculateBaudRate=34.375 MBits/s
SPI1.DataSize=SPI_DATASIZE_8BIT
SPI1.Direction=SPI_DIRECTION_2LINES_TXONLY
SPI1.Mode=SPI_MODE_MASTER
SPI1.VirtualType=VM_MASTER
SPI2.BaudRatePrescaler=SPI_BAUDRATEPRESCALER_32
SPI2.CLKPhase=SPI_PHASE_2EDGE
SPI2.CLKPolarity=SPI_POLARITY_HIGH
SPI2.CalculateBaudRate=4.296875 MBits/s
SPI2.DataSize=SPI_DATASIZE_8BIT
SPI2.Direction=SPI_DIRECTION_2LINES
SPI2.Mode=SPI_MODE_MASTER
SPI2.VirtualType=VM_MASTER
TIM1.Channel-PWM\ Generation1\ CH1=TIM_CHANNEL_1
TIM1.Channel-PWM\ Generation3\ CH3=TIM_CHANNEL_3
TIM1.Period=20000-1
TIM1.Prescaler=275-1
TIM1.Pulse-PWM\ Generation1\ CH1=5000
TIM1.Pulse-PWM\ Generation3\ CH3=5000
TIM12.Channel-PWM\ Generation2\ CH2=TIM_CHANNEL_2
TIM12.Period=2000-1
TIM12.Prescaler=24-1
TIM2.Channel-PWM\ Generation1\ CH1=TIM_CHANNEL_1
TIM2.Channel-PWM\ Generation3\ CH3=TIM_CHANNEL_3
TIM2.Period=20000-1
TIM2.Prescaler=275-1
TIM2.Pulse-PWM\ Generation1\ CH1=5000
TIM2.Pulse-PWM\ Generation3\ CH3=5000
TIM3.AutoReloadPreload=TIM_AUTORELOAD_PRELOAD_ENABLE
TIM3.Channel-PWM\ Generation4\ CH4=TIM_CHANNEL_4
TIM3.Period=10000-1
TIM3.Prescaler=24-1
UART5.BaudRate=100000
UART5.Mode=MODE_TX_RX
UART5.Parity=PARITY_EVEN
UART5.StopBits=UART_STOPBITS_2
UART5.WordLength=WORDLENGTH_9B
UART7.BaudRate=921600
UART8.BaudRate=921600
UART8.FIFOMode=FIFOMODE_ENABLE
UART9.BaudRate=921600
USART1.BaudRate=115200
USART1.FIFOMode=FIFOMODE_DISABLE
USART1.VirtualMode-Asynchronous=VM_ASYNC
USART10.BaudRate=921600
USART10.VirtualMode=VM_ASYNC
USART2.BaudRate=921600
USART2.VirtualMode-Asynchronous=VM_ASYNC
USART2.VirtualMode-Hardware\ Flow\ Control\ (RS485)=VM_ASYNC
USART3.VirtualMode-Asynchronous=VM_ASYNC
USART3.VirtualMode-Hardware\ Flow\ Control\ (RS485)=VM_ASYNC
USB_OTG_HS.VirtualMode-Device_Only_FS=Device_Only_FS
VP_FREERTOS_VS_CMSIS_V2.Mode=CMSIS_V2
VP_MEMORYMAP_VS_MEMORYMAP.Mode=CurAppReg
VP_OCTOSPI2_VS_quad.Mode=quad_mode
VP_SYS_VS_tim8.Mode=TIM8
board=custom

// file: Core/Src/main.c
/* USER CODE BEGIN Header */
/**
  ******************************************************************************
  * @file           : main.c
  * @brief          : Main program body
  ******************************************************************************
  * @attention
  *
  * Copyright (c) 2026 STMicroelectronics.
  * All rights reserved.
  *
  * This software is licensed under terms that can be found in the LICENSE file
  * in the root directory of this software component.
  * If no LICENSE file comes with this software, it is provided AS-IS.
  *
  ******************************************************************************
  */
/* USER CODE END Header */
#include "main.h"
#include "FreeRTOS.h"
#include "cmsis_os2.h"
#include "dma.h"
#include "fdcan.h"
#include "i2c.h"
#include "octospi.h"
#include "spi.h"
#include "tim.h"
#include "usart.h"
#include "usb_otg.h"
#include "gpio.h"

/* USER CODE BEGIN Includes */
#include "app_main.h"
/* USER CODE END Includes */

void SystemClock_Config(void);
void PeriphCommonClock_Config(void);
void MX_FREERTOS_Init(void);

int main(void)
{

  /* MCU Configuration--------------------------------------------------------*/

  /* Reset of all peripherals, Initializes the Flash interface and the Systick. */
  HAL_Init();

  /* Configure the system clock */
  SystemClock_Config();

  /* Configure the peripherals common clocks */
  PeriphCommonClock_Config();

  /* Initialize all configured peripherals */
  MX_GPIO_Init();
  MX_DMA_Init();
  MX_TIM12_Init();
  MX_SPI1_Init();
  MX_SPI2_Init();
  MX_TIM3_Init();
  MX_USART1_UART_Init();
  MX_UART7_Init();
  MX_USART10_UART_Init();
  MX_FDCAN1_Init();
  MX_FDCAN2_Init();
  MX_FDCAN3_Init();
  MX_TIM1_Init();
  MX_TIM2_Init();
  MX_OCTOSPI2_Init();
  MX_USB_OTG_HS_PCD_Init();
  MX_UART8_Init();
  MX_UART9_Init();
  MX_UART4_Init();
  MX_USART2_UART_Init();
  MX_USART3_UART_Init();
  MX_UART5_Init();
  MX_I2C2_Init();

  /* Init scheduler */
  osKernelInitialize();  /* Call init function for freertos objects (in cmsis_os2.c) */
  MX_FREERTOS_Init();

  /* Start scheduler */
  osKernelStart();

  /* We should never get here as control is now taken by the scheduler */

  /* Infinite loop */
  while (1)
  {

  }
}

void SystemClock_Config(void)
{
  RCC_OscInitTypeDef RCC_OscInitStruct = {0};
  RCC_ClkInitTypeDef RCC_ClkInitStruct = {0};

  /** Supply configuration update enable
  */
  HAL_PWREx_ConfigSupply(PWR_LDO_SUPPLY);

  /** Configure the main internal regulator output voltage
  */
  __HAL_PWR_VOLTAGESCALING_CONFIG(PWR_REGULATOR_VOLTAGE_SCALE0);

  while(!__HAL_PWR_GET_FLAG(PWR_FLAG_VOSRDY)) {}

  /** Initializes the RCC Oscillators according to the specified parameters
  * in the RCC_OscInitTypeDef structure.
  */
  RCC_OscInitStruct.OscillatorType = RCC_OSCILLATORTYPE_HSI48|RCC_OSCILLATORTYPE_HSE;
  RCC_OscInitStruct.HSEState = RCC_HSE_ON;
  RCC_OscInitStruct.HSI48State = RCC_HSI48_ON;
  RCC_OscInitStruct.PLL.PLLState = RCC_PLL_ON;
  RCC_OscInitStruct.PLL.PLLSource = RCC_PLLSOURCE_HSE;
  RCC_OscInitStruct.PLL.PLLM = 3;
  RCC_OscInitStruct.PLL.PLLN = 68;
  RCC_OscInitStruct.PLL.PLLP = 1;
  RCC_OscInitStruct.PLL.PLLQ = 4;
  RCC_OscInitStruct.PLL.PLLR = 2;
  RCC_OscInitStruct.PLL.PLLRGE = RCC_PLL1VCIRANGE_3;
  RCC_OscInitStruct.PLL.PLLVCOSEL = RCC_PLL1VCOWIDE;
  RCC_OscInitStruct.PLL.PLLFRACN = 6144;
  if (HAL_RCC_OscConfig(&RCC_OscInitStruct) != HAL_OK)
  {
    Error_Handler();
  }

  /** Initializes the CPU, AHB and APB buses clocks
  */
  RCC_ClkInitStruct.ClockType = RCC_CLOCKTYPE_HCLK|RCC_CLOCKTYPE_SYSCLK
                              |RCC_CLOCKTYPE_PCLK1|RCC_CLOCKTYPE_PCLK2
                              |RCC_CLOCKTYPE_D3PCLK1|RCC_CLOCKTYPE_D1PCLK1;
  RCC_ClkInitStruct.SYSCLKSource = RCC_SYSCLKSOURCE_PLLCLK;
  RCC_ClkInitStruct.SYSCLKDivider = RCC_SYSCLK_DIV1;
  RCC_ClkInitStruct.AHBCLKDivider = RCC_HCLK_DIV2;
  RCC_ClkInitStruct.APB3CLKDivider = RCC_APB3_DIV2;
  RCC_ClkInitStruct.APB1CLKDivider = RCC_APB1_DIV2;
  RCC_ClkInitStruct.APB2CLKDivider = RCC_APB2_DIV2;
  RCC_ClkInitStruct.APB4CLKDivider = RCC_APB4_DIV2;

  if (HAL_RCC_ClockConfig(&RCC_ClkInitStruct, FLASH_LATENCY_3) != HAL_OK)
  {
    Error_Handler();
  }
}

void PeriphCommonClock_Config(void)
{
  RCC_PeriphCLKInitTypeDef PeriphClkInitStruct = {0};

  /** Initializes the peripherals clock
  */
  PeriphClkInitStruct.PeriphClockSelection = RCC_PERIPHCLK_FDCAN;
  PeriphClkInitStruct.PLL2.PLL2M = 2;
  PeriphClkInitStruct.PLL2.PLL2N = 16;
  PeriphClkInitStruct.PLL2.PLL2P = 2;
  PeriphClkInitStruct.PLL2.PLL2Q = 2;
  PeriphClkInitStruct.PLL2.PLL2R = 2;
  PeriphClkInitStruct.PLL2.PLL2RGE = RCC_PLL2VCIRANGE_3;
  PeriphClkInitStruct.PLL2.PLL2VCOSEL = RCC_PLL2VCOWIDE;
  PeriphClkInitStruct.PLL2.PLL2FRACN = 0;
  PeriphClkInitStruct.FdcanClockSelection = RCC_FDCANCLKSOURCE_PLL2;
  if (HAL_RCCEx_PeriphCLKConfig(&PeriphClkInitStruct) != HAL_OK)
  {
    Error_Handler();
  }
}

void HAL_TIM_PeriodElapsedCallback(TIM_HandleTypeDef *htim)
{
  if (htim->Instance == TIM8)
  {
    HAL_IncTick();
  }
}

void Error_Handler(void)
{
  __disable_irq();
  while (1)
  {
  }
}

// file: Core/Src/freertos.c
/* USER CODE BEGIN Header */
/**
  ******************************************************************************
  * File Name          : freertos.c
  * Description        : Code for freertos applications
  ******************************************************************************
  * @attention
  *
  * Copyright (c) 2026 STMicroelectronics.
  * All rights reserved.
  *
  * This software is licensed under terms that can be found in the LICENSE file
  * in the root directory of this software component.
  * If no LICENSE file comes with this software, it is provided AS-IS.
  *
  ******************************************************************************
  */
/* USER CODE END Header */

#include "FreeRTOS.h"
#include "task.h"
#include "main.h"
#include "FreeRTOS.h"
#include "cmsis_os2.h"

/* USER CODE BEGIN Includes */
#include "app_main.h"
/* USER CODE END Includes */

/* Definitions for defaultTask */
osThreadId_t defaultTaskHandle;
const osThreadAttr_t defaultTask_attributes = {
  .name = "defaultTask",
  .stack_size = 512 * 4,
  .priority = (osPriority_t) osPriorityNormal,
};

void StartDefaultTask(void *argument);

void MX_FREERTOS_Init(void); /* (MISRA C 2004 rule 8.1) */

/* Hook prototypes */
void vApplicationStackOverflowHook(xTaskHandle xTask, char *pcTaskName);
void vApplicationMallocFailedHook(void);

/* USER CODE BEGIN 4 */
void vApplicationStackOverflowHook(xTaskHandle xTask, char *pcTaskName)
{
  (void)xTask;
  fault_on_stack_overflow(pcTaskName); /* 记下溢出的任务名后停机，不返回 */
}
/* USER CODE END 4 */

/* USER CODE BEGIN 5 */
void vApplicationMallocFailedHook(void)
{
  fault_on_malloc_failed(); /* 记下当前任务名后停机，不返回 */
}
/* USER CODE END 5 */

void MX_FREERTOS_Init(void) {
  /* USER CODE BEGIN Init */
  app_init(); /* 库入口 → 板级初始化 → 业务任务 → 放行，见 app_main.cpp */
  /* USER CODE END Init */

  /* Create the thread(s) */
  /* creation of defaultTask */
  defaultTaskHandle = osThreadNew(StartDefaultTask, NULL, &defaultTask_attributes);

  /* USER CODE BEGIN RTOS_THREADS */
  configASSERT(defaultTaskHandle != NULL);
  /* USER CODE END RTOS_THREADS */

}

__weak void StartDefaultTask(void *argument)
{
  for(;;)
  {
    osDelay(1);
  }
}
